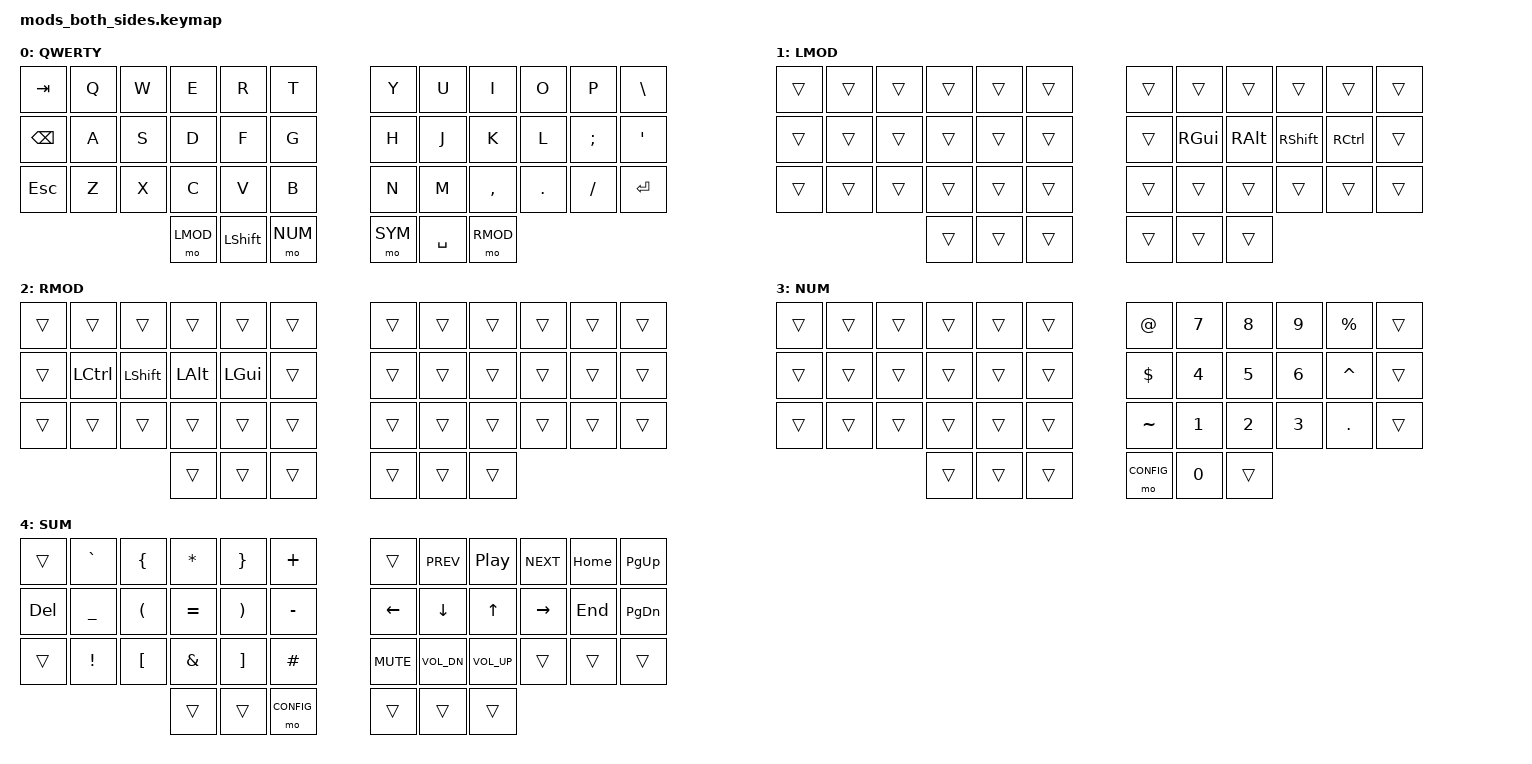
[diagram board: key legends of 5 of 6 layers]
/*
*
* Copyright (c) 2021 Darryl deHaan
* SPDX-License-Identifier: MIT
*
*/

#include <behaviors.dtsi>
#include <dt-bindings/zmk/keys.h>
#include <dt-bindings/zmk/bt.h>

#define QWERTY 0
#define LMOD   1
#define RMOD   2
#define NUM    3
#define SYM    4
#define CONFIG 5

/ {
        keymap {
                compatible = "zmk,keymap";

                default_layer {
                        label = "QWERTY";
// -----------------------------------------------------------------------------------------
// | TAB  |  Q  |  W  |  E  |  R  |  T  |   |  Y  |  U   |  I  |  O  |  P  | \     |
// | BKSP |  A  |  S  |  D  |  F  |  G  |   |  H  |  J   |  K  |  L  |  ;  |  '    |
// | ESC  |  Z  |  X  |  C  |  V  |  B  |   |  N  |  M   |  ,  |  .  |  /  | ENTER |
//                | LMOD | LSHIFT | NUM |   | SYM | SPACE  | RMOD |
                        bindings = <
   &kp TAB   &kp Q &kp W &kp E &kp R &kp T   &kp Y &kp U  &kp I     &kp O   &kp P    &kp BSLH
   &kp BSPC  &kp A &kp S &kp D &kp F &kp G   &kp H &kp J  &kp K     &kp L   &kp SEMI &kp SQT
   &kp ESC   &kp Z &kp X &kp C &kp V &kp B   &kp N &kp M  &kp COMMA &kp DOT &kp FSLH &kp ENTER
               &mo LMOD &kp LSHIFT &mo NUM   &mo SYM &kp SPACE &mo RMOD
                        >;
                };
                
                rmods {
                    label = "LMOD";
                    bindings = <
        &trans &trans &trans &trans &trans &trans        &trans &trans   &trans   &trans    &trans    &trans 
        &trans &trans &trans &trans &trans &trans        &trans &kp RGUI &kp RALT &kp RSHFT &kp RCTRL &trans 
        &trans &trans &trans &trans &trans &trans        &trans &trans   &trans   &trans    &trans    &trans 
                             &trans &trans &trans        &trans &trans   &trans
                    >;
                };

                lmods {
                    label = "RMOD";
                    bindings = <
        &trans &trans    &trans    &trans   &trans   &trans        &trans &trans &trans &trans &trans &trans 
        &trans &kp LCTRL &kp LSHFT &kp LALT &kp LGUI &trans        &trans &trans &trans &trans &trans &trans 
        &trans &trans    &trans    &trans   &trans   &trans        &trans &trans &trans &trans &trans &trans
                                   &trans   &trans   &trans        &trans &trans &trans
                    >;
                };

                num {
                    label = "NUM";
                    bindings = <
        &trans &trans &trans &trans &trans &trans        &kp AT     &kp N7 &kp N8 &kp N9 &kp PERCENT &trans
        &trans &trans &trans &trans &trans &trans        &kp DLLR   &kp N4 &kp N5 &kp N6 &kp CARET   &trans
        &trans &trans &trans &trans &trans &trans        &kp TILDE  &kp N1 &kp N2 &kp N3 &kp DOT     &trans
                             &trans &trans &trans        &mo CONFIG &kp N0 &trans
                    >;
                };

                sym {
                    label = "SUM";
                    bindings = <
        &trans  &kp GRAVE &kp LBRC &kp ASTRK &kp RBRC &kp PLUS          &trans     &kp C_PREV   &kp C_PLAY_PAUSE &kp C_NEXT &kp HOME &kp PG_UP
        &kp DEL &kp UNDER &kp LPAR &kp EQUAL &kp RPAR &kp MINUS         &kp LEFT   &kp DOWN     &kp UP           &kp RIGHT  &kp END  &kp PG_DN
        &trans  &kp EXCL  &kp LBKT &kp AMPS  &kp RBKT &kp HASH          &kp K_MUTE &kp K_VOL_DN &kp K_VOL_UP     &trans     &trans   &trans
                                  &trans    &trans   &mo CONFIG         &trans     &trans       &trans
                    >;
                };

                config_layer {
                        label = "CONFIG";
                        bindings = <
   &reset     &none        &none        &none        &none        &none           &none &none &none &none &none &none 
   &bt BT_CLR &bt BT_SEL 0 &bt BT_SEL 1 &bt BT_SEL 2 &bt BT_SEL 3 &bt BT_SEL 4    &none &none &none &none &none &none
   &none      &none        &none        &none        &none        &none           &none &none &none &none &none &none
                                                &mo CONFIG &kp LCTL &mo NUM       &kp SPC &mo &none &kp F13
                        >;
                };

        };
};
